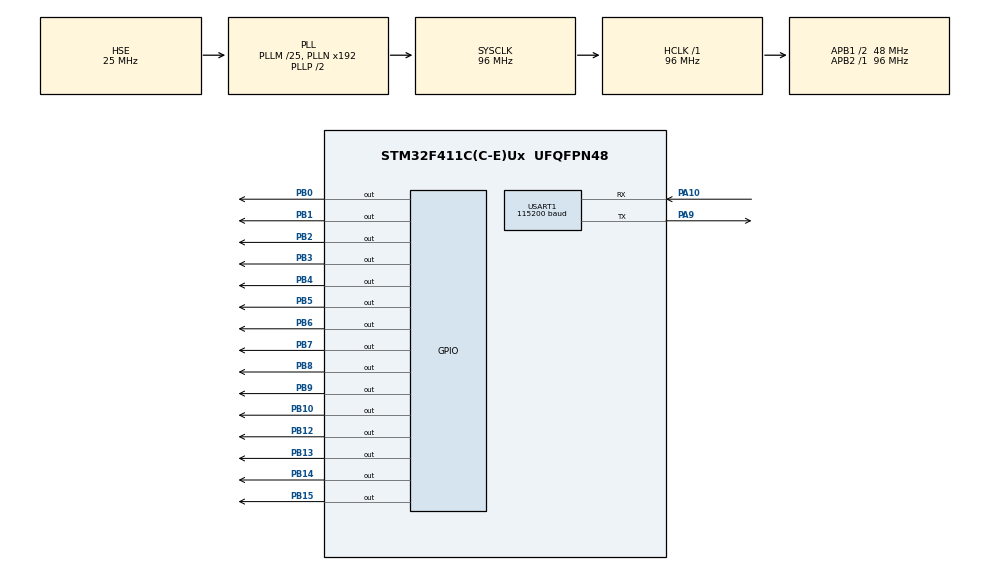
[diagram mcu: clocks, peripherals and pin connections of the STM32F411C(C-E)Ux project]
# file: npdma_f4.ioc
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ADC1.Channel-2\#ChannelRegularConversion=ADC_CHANNEL_TEMPSENSOR
ADC1.NbrOfConversionFlag=1
ADC1.Rank-2\#ChannelRegularConversion=1
ADC1.SamplingTime-2\#ChannelRegularConversion=ADC_SAMPLETIME_3CYCLES
ADC1.master=1
Dma.Request0=TIM1_UP
Dma.Request1=TIM1_CH1
Dma.Request2=TIM1_CH2
Dma.TIM1_CH1.1.Direction=DMA_MEMORY_TO_PERIPH
Dma.TIM1_CH1.1.FIFOMode=DMA_FIFOMODE_DISABLE
Dma.TIM1_CH1.1.Instance=DMA2_Stream1
Dma.TIM1_CH1.1.MemDataAlignment=DMA_MDATAALIGN_WORD
Dma.TIM1_CH1.1.MemInc=DMA_MINC_ENABLE
Dma.TIM1_CH1.1.Mode=DMA_CIRCULAR
Dma.TIM1_CH1.1.PeriphDataAlignment=DMA_PDATAALIGN_WORD
Dma.TIM1_CH1.1.PeriphInc=DMA_PINC_DISABLE
Dma.TIM1_CH1.1.Priority=DMA_PRIORITY_VERY_HIGH
Dma.TIM1_CH2.2.Direction=DMA_MEMORY_TO_PERIPH
Dma.TIM1_CH2.2.FIFOMode=DMA_FIFOMODE_DISABLE
Dma.TIM1_CH2.2.Instance=DMA2_Stream2
Dma.TIM1_CH2.2.MemDataAlignment=DMA_MDATAALIGN_WORD
Dma.TIM1_CH2.2.MemInc=DMA_MINC_DISABLE
Dma.TIM1_CH2.2.Mode=DMA_CIRCULAR
Dma.TIM1_CH2.2.PeriphDataAlignment=DMA_PDATAALIGN_WORD
Dma.TIM1_CH2.2.PeriphInc=DMA_PINC_DISABLE
Dma.TIM1_CH2.2.Priority=DMA_PRIORITY_VERY_HIGH
Dma.TIM1_UP.0.Direction=DMA_MEMORY_TO_PERIPH
Dma.TIM1_UP.0.FIFOMode=DMA_FIFOMODE_DISABLE
Dma.TIM1_UP.0.Instance=DMA2_Stream5
Dma.TIM1_UP.0.MemDataAlignment=DMA_MDATAALIGN_WORD
Dma.TIM1_UP.0.MemInc=DMA_MINC_DISABLE
Dma.TIM1_UP.0.Mode=DMA_CIRCULAR
Dma.TIM1_UP.0.PeriphDataAlignment=DMA_PDATAALIGN_WORD
Dma.TIM1_UP.0.PeriphInc=DMA_PINC_DISABLE
Dma.TIM1_UP.0.Priority=DMA_PRIORITY_VERY_HIGH
Mcu.Family=STM32F4
Mcu.Name=STM32F411C(C-E)Ux
Mcu.Package=UFQFPN48
NVIC.DMA2_Stream1_IRQn=true\:0\:0\:false\:false\:true\:false\:true
NVIC.DMA2_Stream2_IRQn=true\:0\:0\:false\:false\:true\:false\:true
NVIC.DMA2_Stream5_IRQn=true\:0\:0\:false\:false\:true\:false\:true
NVIC.PriorityGroup=NVIC_PRIORITYGROUP_4
PA10.Mode=Asynchronous
PA10.Signal=USART1_RX
PA13.Mode=Serial_Wire
PA13.Signal=SYS_JTMS-SWDIO
PA14.Mode=Serial_Wire
PA14.Signal=SYS_JTCK-SWCLK
PA9.Mode=Asynchronous
PA9.Signal=USART1_TX
PB0.GPIO_Speed=GPIO_SPEED_FREQ_VERY_HIGH
PB0.Signal=GPIO_Output
PB1.GPIO_Speed=GPIO_SPEED_FREQ_VERY_HIGH
PB1.Signal=GPIO_Output
PB10.GPIO_Speed=GPIO_SPEED_FREQ_VERY_HIGH
PB10.Signal=GPIO_Output
PB12.GPIO_Speed=GPIO_SPEED_FREQ_VERY_HIGH
PB12.Signal=GPIO_Output
PB13.GPIO_Speed=GPIO_SPEED_FREQ_VERY_HIGH
PB13.Signal=GPIO_Output
PB14.GPIO_Speed=GPIO_SPEED_FREQ_VERY_HIGH
PB14.Signal=GPIO_Output
PB15.GPIO_Speed=GPIO_SPEED_FREQ_VERY_HIGH
PB15.Signal=GPIO_Output
PB2.GPIO_Speed=GPIO_SPEED_FREQ_VERY_HIGH
PB2.Signal=GPIO_Output
PB3.GPIO_Speed=GPIO_SPEED_FREQ_VERY_HIGH
PB3.Signal=GPIO_Output
PB4.GPIO_Speed=GPIO_SPEED_FREQ_VERY_HIGH
PB4.Signal=GPIO_Output
PB5.GPIO_Speed=GPIO_SPEED_FREQ_VERY_HIGH
PB5.Signal=GPIO_Output
PB6.GPIO_Speed=GPIO_SPEED_FREQ_VERY_HIGH
PB6.Signal=GPIO_Output
PB7.GPIO_Speed=GPIO_SPEED_FREQ_VERY_HIGH
PB7.Signal=GPIO_Output
PB8.GPIO_Speed=GPIO_SPEED_FREQ_VERY_HIGH
PB8.Signal=GPIO_Output
PB9.GPIO_Speed=GPIO_SPEED_FREQ_VERY_HIGH
PB9.Signal=GPIO_Output
PH0\ -\ OSC_IN.Mode=HSE-External-Oscillator
PH0\ -\ OSC_IN.Signal=RCC_OSC_IN
PH1\ -\ OSC_OUT.Mode=HSE-External-Oscillator
PH1\ -\ OSC_OUT.Signal=RCC_OSC_OUT
ProjectManager.HeapSize=0x200
ProjectManager.StackSize=0x400
ProjectManager.TargetToolchain=Makefile
RCC.48MHZClocksFreq_Value=48000000
RCC.AHBFreq_Value=96000000
RCC.APB1CLKDivider=RCC_HCLK_DIV2
RCC.APB1Freq_Value=48000000
RCC.APB1TimFreq_Value=96000000
RCC.APB2Freq_Value=96000000
RCC.APB2TimFreq_Value=96000000
RCC.CortexFreq_Value=96000000
RCC.HCLKFreq_Value=96000000
RCC.HSE_VALUE=25000000
RCC.HSI_VALUE=16000000
RCC.LSE_VALUE=32768
RCC.PLLM=25
RCC.PLLSourceVirtual=RCC_PLLSOURCE_HSE
RCC.SYSCLKFreq_VALUE=96000000
RCC.SYSCLKSource=RCC_SYSCLKSOURCE_PLLCLK
RCC.VCOOutputFreq_Value=192000000
TIM1.Channel-PWM\ Generation1\ No\ Output=TIM_CHANNEL_1
TIM1.Channel-PWM\ Generation2\ No\ Output=TIM_CHANNEL_2
TIM1.OC1Preload_PWM=DISABLE
TIM1.OC2Preload_PWM=DISABLE
TIM1.RepetitionCounter=0x0
USART1.BaudRate=115200
USART1.VirtualMode=VM_ASYNC
VP_ADC1_TempSens_Input.Mode=IN-TempSens
VP_TIM1_VS_ClockSourceINT.Mode=Internal
VP_TIM1_VS_no_output1.Mode=PWM Generation1 No Output
VP_TIM1_VS_no_output2.Mode=PWM Generation2 No Output
board=custom

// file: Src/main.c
/* USER CODE BEGIN Header */
/**
  ******************************************************************************
  * @file           : main.c
  * @brief          : Main program body
  ******************************************************************************
  * @attention
  *
  * <h2><center>&copy; Copyright (c) 2021 STMicroelectronics.
  * All rights reserved.</center></h2>
  *
  * This software component is licensed by ST under BSD 3-Clause license,
  * the "License"; You may not use this file except in compliance with the
  * License. You may obtain a copy of the License at:
  *                        opensource.org/licenses/BSD-3-Clause
  *
  ******************************************************************************
  */
/* USER CODE END Header */

#include "main.h"

ADC_HandleTypeDef hadc1;

TIM_HandleTypeDef htim1;
DMA_HandleTypeDef hdma_tim1_up;
DMA_HandleTypeDef hdma_tim1_ch1;
DMA_HandleTypeDef hdma_tim1_ch2;

UART_HandleTypeDef huart1;

void SystemClock_Config(void);
static void MX_GPIO_Init(void);
void MX_DMA_Init(void);
static void MX_USART1_UART_Init(void);
static void MX_ADC1_Init(void);
static void MX_TIM1_Init(void);

/* USER CODE BEGIN 0 */
int demo_main(void);
/* USER CODE END 0 */

int main(void)
{

  /* MCU Configuration--------------------------------------------------------*/

  /* Reset of all peripherals, Initializes the Flash interface and the Systick. */
  HAL_Init();

  /* Configure the system clock */
  SystemClock_Config();

  /* Initialize all configured peripherals */
  MX_GPIO_Init();
  MX_DMA_Init();
  MX_USART1_UART_Init();
  MX_ADC1_Init();
  MX_TIM1_Init();
  /* USER CODE BEGIN 2 */
  demo_main();
  /* USER CODE END 2 */

  /* Infinite loop */
  while (1)
  {

  }
}

void SystemClock_Config(void)
{
  RCC_OscInitTypeDef RCC_OscInitStruct = {0};
  RCC_ClkInitTypeDef RCC_ClkInitStruct = {0};

  /** Configure the main internal regulator output voltage
  */
  __HAL_RCC_PWR_CLK_ENABLE();
  __HAL_PWR_VOLTAGESCALING_CONFIG(PWR_REGULATOR_VOLTAGE_SCALE1);
  /** Initializes the CPU, AHB and APB busses clocks
  */
  RCC_OscInitStruct.OscillatorType = RCC_OSCILLATORTYPE_HSE;
  RCC_OscInitStruct.HSEState = RCC_HSE_ON;
  RCC_OscInitStruct.PLL.PLLState = RCC_PLL_ON;
  RCC_OscInitStruct.PLL.PLLSource = RCC_PLLSOURCE_HSE;
  RCC_OscInitStruct.PLL.PLLM = 25;
  RCC_OscInitStruct.PLL.PLLN = 192;
  RCC_OscInitStruct.PLL.PLLP = RCC_PLLP_DIV2;
  RCC_OscInitStruct.PLL.PLLQ = 4;
  if (HAL_RCC_OscConfig(&RCC_OscInitStruct) != HAL_OK)
  {
    Error_Handler();
  }
  /** Initializes the CPU, AHB and APB busses clocks
  */
  RCC_ClkInitStruct.ClockType = RCC_CLOCKTYPE_HCLK|RCC_CLOCKTYPE_SYSCLK
                              |RCC_CLOCKTYPE_PCLK1|RCC_CLOCKTYPE_PCLK2;
  RCC_ClkInitStruct.SYSCLKSource = RCC_SYSCLKSOURCE_PLLCLK;
  RCC_ClkInitStruct.AHBCLKDivider = RCC_SYSCLK_DIV1;
  RCC_ClkInitStruct.APB1CLKDivider = RCC_HCLK_DIV2;
  RCC_ClkInitStruct.APB2CLKDivider = RCC_HCLK_DIV1;

  if (HAL_RCC_ClockConfig(&RCC_ClkInitStruct, FLASH_LATENCY_3) != HAL_OK)
  {
    Error_Handler();
  }
}

static void MX_ADC1_Init(void)
{

  ADC_ChannelConfTypeDef sConfig = {0};

  /** Configure the global features of the ADC (Clock, Resolution, Data Alignment and number of conversion)
  */
  hadc1.Instance = ADC1;
  hadc1.Init.ClockPrescaler = ADC_CLOCK_SYNC_PCLK_DIV4;
  hadc1.Init.Resolution = ADC_RESOLUTION_12B;
  hadc1.Init.ScanConvMode = DISABLE;
  hadc1.Init.ContinuousConvMode = DISABLE;
  hadc1.Init.DiscontinuousConvMode = DISABLE;
  hadc1.Init.ExternalTrigConvEdge = ADC_EXTERNALTRIGCONVEDGE_NONE;
  hadc1.Init.ExternalTrigConv = ADC_SOFTWARE_START;
  hadc1.Init.DataAlign = ADC_DATAALIGN_RIGHT;
  hadc1.Init.NbrOfConversion = 1;
  hadc1.Init.DMAContinuousRequests = DISABLE;
  hadc1.Init.EOCSelection = ADC_EOC_SINGLE_CONV;
  if (HAL_ADC_Init(&hadc1) != HAL_OK)
  {
    Error_Handler();
  }
  /** Configure for the selected ADC regular channel its corresponding rank in the sequencer and its sample time.
  */
  sConfig.Channel = ADC_CHANNEL_TEMPSENSOR;
  sConfig.Rank = 1;
  sConfig.SamplingTime = ADC_SAMPLETIME_3CYCLES;
  if (HAL_ADC_ConfigChannel(&hadc1, &sConfig) != HAL_OK)
  {
    Error_Handler();
  }

}

static void MX_TIM1_Init(void)
{

  TIM_ClockConfigTypeDef sClockSourceConfig = {0};
  TIM_MasterConfigTypeDef sMasterConfig = {0};
  TIM_OC_InitTypeDef sConfigOC = {0};
  TIM_BreakDeadTimeConfigTypeDef sBreakDeadTimeConfig = {0};

  htim1.Instance = TIM1;
  htim1.Init.Prescaler = 0;
  htim1.Init.CounterMode = TIM_COUNTERMODE_UP;
  htim1.Init.Period = 0;
  htim1.Init.ClockDivision = TIM_CLOCKDIVISION_DIV1;
  htim1.Init.RepetitionCounter = 0x0;
  htim1.Init.AutoReloadPreload = TIM_AUTORELOAD_PRELOAD_DISABLE;
  if (HAL_TIM_Base_Init(&htim1) != HAL_OK)
  {
    Error_Handler();
  }
  sClockSourceConfig.ClockSource = TIM_CLOCKSOURCE_INTERNAL;
  if (HAL_TIM_ConfigClockSource(&htim1, &sClockSourceConfig) != HAL_OK)
  {
    Error_Handler();
  }
  if (HAL_TIM_PWM_Init(&htim1) != HAL_OK)
  {
    Error_Handler();
  }
  sMasterConfig.MasterOutputTrigger = TIM_TRGO_RESET;
  sMasterConfig.MasterSlaveMode = TIM_MASTERSLAVEMODE_DISABLE;
  if (HAL_TIMEx_MasterConfigSynchronization(&htim1, &sMasterConfig) != HAL_OK)
  {
    Error_Handler();
  }
  sConfigOC.OCMode = TIM_OCMODE_PWM1;
  sConfigOC.Pulse = 0;
  sConfigOC.OCPolarity = TIM_OCPOLARITY_HIGH;
  sConfigOC.OCNPolarity = TIM_OCNPOLARITY_HIGH;
  sConfigOC.OCFastMode = TIM_OCFAST_DISABLE;
  sConfigOC.OCIdleState = TIM_OCIDLESTATE_RESET;
  sConfigOC.OCNIdleState = TIM_OCNIDLESTATE_RESET;
  if (HAL_TIM_PWM_ConfigChannel(&htim1, &sConfigOC, TIM_CHANNEL_1) != HAL_OK)
  {
    Error_Handler();
  }
  __HAL_TIM_DISABLE_OCxPRELOAD(&htim1, TIM_CHANNEL_1);
  if (HAL_TIM_PWM_ConfigChannel(&htim1, &sConfigOC, TIM_CHANNEL_2) != HAL_OK)
  {
    Error_Handler();
  }
  __HAL_TIM_DISABLE_OCxPRELOAD(&htim1, TIM_CHANNEL_2);
  sBreakDeadTimeConfig.OffStateRunMode = TIM_OSSR_DISABLE;
  sBreakDeadTimeConfig.OffStateIDLEMode = TIM_OSSI_DISABLE;
  sBreakDeadTimeConfig.LockLevel = TIM_LOCKLEVEL_OFF;
  sBreakDeadTimeConfig.DeadTime = 0;
  sBreakDeadTimeConfig.BreakState = TIM_BREAK_DISABLE;
  sBreakDeadTimeConfig.BreakPolarity = TIM_BREAKPOLARITY_HIGH;
  sBreakDeadTimeConfig.AutomaticOutput = TIM_AUTOMATICOUTPUT_DISABLE;
  if (HAL_TIMEx_ConfigBreakDeadTime(&htim1, &sBreakDeadTimeConfig) != HAL_OK)
  {
    Error_Handler();
  }

}

static void MX_USART1_UART_Init(void)
{

  huart1.Instance = USART1;
  huart1.Init.BaudRate = 115200;
  huart1.Init.WordLength = UART_WORDLENGTH_8B;
  huart1.Init.StopBits = UART_STOPBITS_1;
  huart1.Init.Parity = UART_PARITY_NONE;
  huart1.Init.Mode = UART_MODE_TX_RX;
  huart1.Init.HwFlowCtl = UART_HWCONTROL_NONE;
  huart1.Init.OverSampling = UART_OVERSAMPLING_16;
  if (HAL_UART_Init(&huart1) != HAL_OK)
  {
    Error_Handler();
  }

}

void MX_DMA_Init(void)
{

  /* DMA controller clock enable */
  __HAL_RCC_DMA2_CLK_ENABLE();

  /* DMA interrupt init */
  /* DMA2_Stream1_IRQn interrupt configuration */
  HAL_NVIC_SetPriority(DMA2_Stream1_IRQn, 0, 0);
  HAL_NVIC_EnableIRQ(DMA2_Stream1_IRQn);
  /* DMA2_Stream2_IRQn interrupt configuration */
  HAL_NVIC_SetPriority(DMA2_Stream2_IRQn, 0, 0);
  HAL_NVIC_EnableIRQ(DMA2_Stream2_IRQn);
  /* DMA2_Stream5_IRQn interrupt configuration */
  HAL_NVIC_SetPriority(DMA2_Stream5_IRQn, 0, 0);
  HAL_NVIC_EnableIRQ(DMA2_Stream5_IRQn);

}

static void MX_GPIO_Init(void)
{
  GPIO_InitTypeDef GPIO_InitStruct = {0};

  /* GPIO Ports Clock Enable */
  __HAL_RCC_GPIOH_CLK_ENABLE();
  __HAL_RCC_GPIOB_CLK_ENABLE();
  __HAL_RCC_GPIOA_CLK_ENABLE();

  /*Configure GPIO pin Output Level */
  HAL_GPIO_WritePin(GPIOB, GPIO_PIN_0|GPIO_PIN_1|GPIO_PIN_2|GPIO_PIN_10
                          |GPIO_PIN_12|GPIO_PIN_13|GPIO_PIN_14|GPIO_PIN_15
                          |GPIO_PIN_3|GPIO_PIN_4|GPIO_PIN_5|GPIO_PIN_6
                          |GPIO_PIN_7|GPIO_PIN_8|GPIO_PIN_9, GPIO_PIN_RESET);

  /*Configure GPIO pins : PB0 PB1 PB2 PB10
                           PB12 PB13 PB14 PB15
                           PB3 PB4 PB5 PB6
                           PB7 PB8 PB9 */
  GPIO_InitStruct.Pin = GPIO_PIN_0|GPIO_PIN_1|GPIO_PIN_2|GPIO_PIN_10
                          |GPIO_PIN_12|GPIO_PIN_13|GPIO_PIN_14|GPIO_PIN_15
                          |GPIO_PIN_3|GPIO_PIN_4|GPIO_PIN_5|GPIO_PIN_6
                          |GPIO_PIN_7|GPIO_PIN_8|GPIO_PIN_9;
  GPIO_InitStruct.Mode = GPIO_MODE_OUTPUT_PP;
  GPIO_InitStruct.Pull = GPIO_NOPULL;
  GPIO_InitStruct.Speed = GPIO_SPEED_FREQ_VERY_HIGH;
  HAL_GPIO_Init(GPIOB, &GPIO_InitStruct);

}

void Error_Handler(void)
{
}

/************************ (C) COPYRIGHT STMicroelectronics *****END OF FILE****/
